# TestDevice register map
Vendor: TestVendor; File version: 1.0
A minimal test device for svdgen unit tests
CPU: CM4 r0p1, little endian, MPU, FPU, 4 interrupt priority bits
Registers are 32-bit, read-write, reset 0x0 unless marked. A register's access mark holds for its fields unless they carry their own. Offsets are from the block's base; lines under a group give offsets from that group; [hi:lo] are bit positions; {n}, {i} and the like mark numbered series; 'fields as' and 'values as' point back to an identical list; <NAME> marks a mode.

## Memory map
0x40020000 GPIOA size 0x400 — General purpose I/O port A
0x40020400 GPIOB size 0x400 — General purpose I/O port B

## Interrupts
6 GPIOA_IRQ (GPIOA) — GPIOA global interrupt
7 GPIOB_IRQ (GPIOB) — GPIOB global interrupt

## GPIOA — General purpose I/O port A
Base 0x40020000
Same registers: GPIOB 0x40020400
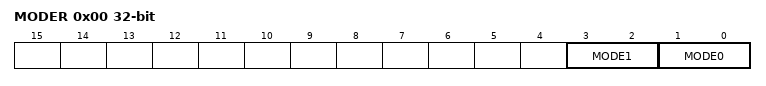
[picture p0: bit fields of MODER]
0x00 MODER — GPIO port mode register
  [3:2] MODE1 — Port x configuration bits (y = 1)
  [1:0] MODE0 — Port x configuration bits (y = 0)
    0=Input mode; 1=Output (General purpose output mode)
0x14 ODR — GPIO port output data register
  [0] OD0 — Port output data bit 0
